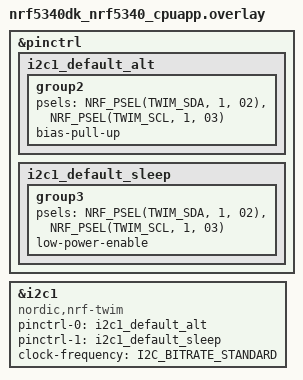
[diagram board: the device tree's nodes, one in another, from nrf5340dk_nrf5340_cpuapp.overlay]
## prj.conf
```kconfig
CONFIG_I2C=y
CONFIG_SHELL=y
CONFIG_I2C_SHELL=y
CONFIG_PRINTK=y
```

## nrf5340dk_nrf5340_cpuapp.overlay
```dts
&pinctrl {
	i2c1_default_alt: i2c1_default_alt {
		group2 {
			psels = <NRF_PSEL(TWIM_SDA, 1, 02)>, <NRF_PSEL(TWIM_SCL, 1, 03)>;
			bias-pull-up;
		};
	};

	i2c1_default_sleep: i2c1_default_sleep {
		group3 {
			psels = <NRF_PSEL(TWIM_SDA, 1, 02)>, <NRF_PSEL(TWIM_SCL, 1, 03)>;
			low-power-enable;
		};
	};
};


&i2c1 {
	status = "okay";
	compatible = "nordic,nrf-twim";
	pinctrl-0 = <&i2c1_default_alt>;
	pinctrl-1 = <&i2c1_default_sleep>;
	pinctrl-names = "default", "sleep";
	clock-frequency = < I2C_BITRATE_STANDARD >;
    // sts40: sts40@46 {    /* STS40 I2C address is 0x46 */
    //     compatible = "i2c-device";
    //     status = "okay";
    //     reg = <0x46>;
    //     label = "STS40";

    // };
};
```

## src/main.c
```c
#include <zephyr/kernel.h>
#include<zephyr/sys/printk.h>
int main(void)
{
#ifdef CONFIG_PRINTK
	printk("Hello World from minimal!\n");
#endif

	return 0;
}
```
